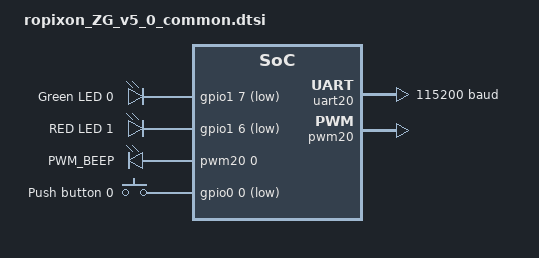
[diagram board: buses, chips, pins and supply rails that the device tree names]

/*
 * filepath: c:\Work\99_Witc\ZG_Repo\ZoneGuard\boards\Ropixon\ropixon_ZG_v5_0\ropixon_ZG_v5_0_common.dtsi
 * Copyright (c) 2024 Nordic Semiconductor ASA
 *
 * SPDX-License-Identifier: Apache-2.0
 */

 
#include "ropixon_ZG_v5_0-pinctrl.dtsi"


/ {
	leds {
		compatible = "gpio-leds";
		led0: led_0 {
			gpios = <&gpio1 7 GPIO_ACTIVE_LOW>;
			label = "Green LED 0";
			status = "okay";
		};
		led1: led_1 {
			gpios = <&gpio1 6 GPIO_ACTIVE_LOW>;
			label = "RED LED 1";
			status = "okay";
		};
	};

	// pwmleds {
	// 	compatible = "pwm-leds";
	// 	/*
	// 	 * PWM signal can be exposed on GPIO pin only within same domain.
	// 	 * There is only one domain which contains both PWM and GPIO:
	// 	 * PWM20/21/22 and GPIO Port P1.
	// 	 * Only LEDs connected to P1 can work with PWM, for example LED1.
	// 	 */
	// 	pwm_led1: pwm_led_1 {
	// 		pwms = <&pwm20 0 PWM_MSEC(20) PWM_POLARITY_NORMAL>;
	// 		status = "okay";
	// 	};
	// };

	pwm_beep: pwm_beep {
        compatible = "pwm-leds";
        pwm_buzzer: buzzer {
            pwms = <&pwm20 0 1000000 PWM_POLARITY_NORMAL>;
            label = "PWM_BEEP";
        };
    };


	buttons {
		compatible = "gpio-keys";
		button0: button_0 {
			gpios = <&gpio0 0 (GPIO_PULL_UP | GPIO_ACTIVE_LOW)>;
			label = "Push button 0";
			zephyr,code = <INPUT_KEY_0>;
			status = "okay";
		};
	};

	aliases {
		led0 = &led0;
		led1 = &led1;
		buzzer = &pwm_buzzer;
		button0 = &button0;
		//watchdog0 = &wdt31;
	};
};

&uart20 {
	current-speed = <115200>;
	pinctrl-0 = <&uart20_default>;
	pinctrl-1 = <&uart20_sleep>;
	pinctrl-names = "default", "sleep";
};


&pwm20 {
	status = "okay";
	pinctrl-0 = <&pwm20_default>;
	pinctrl-1 = <&pwm20_sleep>;
	pinctrl-names = "default", "sleep";
};

